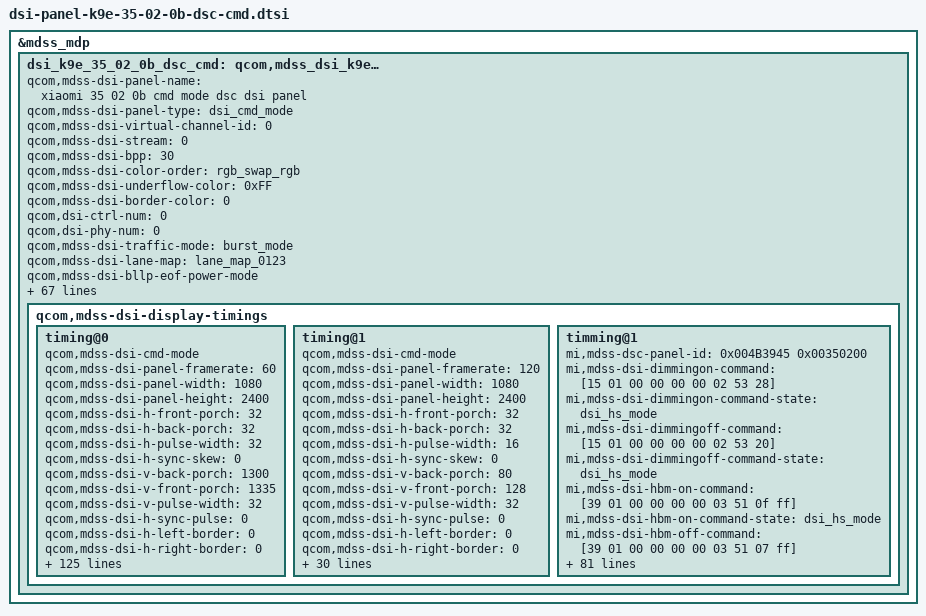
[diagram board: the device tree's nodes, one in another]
&mdss_mdp {
	dsi_k9e_35_02_0b_dsc_cmd: qcom,mdss_dsi_k9e_35_02_0b_dsc_cmd {
		qcom,mdss-dsi-panel-name = "xiaomi 35 02 0b cmd mode dsc dsi panel";
		qcom,mdss-dsi-panel-type = "dsi_cmd_mode";
		qcom,mdss-dsi-virtual-channel-id = <0>;
		qcom,mdss-dsi-stream = <0>;
		qcom,mdss-dsi-bpp = <30>;
		qcom,mdss-dsi-color-order = "rgb_swap_rgb";
		qcom,mdss-dsi-underflow-color = <0xFF>;
		qcom,mdss-dsi-border-color = <0>;
		qcom,dsi-ctrl-num = <0>;
		qcom,dsi-phy-num = <0>;
		qcom,mdss-dsi-traffic-mode = "burst_mode";
		qcom,mdss-dsi-lane-map = "lane_map_0123";
		qcom,mdss-dsi-bllp-eof-power-mode;
		qcom,mdss-dsi-bllp-power-mode;
		qcom,mdss-dsi-lane-0-state;
		qcom,mdss-dsi-lane-1-state;
		qcom,mdss-dsi-lane-2-state;
		qcom,mdss-dsi-lane-3-state;
		qcom,mdss-dsi-dma-trigger = "trigger_sw";
		qcom,mdss-dsi-mdp-trigger = "none";
		qcom,mdss-dsi-reset-sequence = <1 11>, <0 1>, <1 11>;
		qcom,mdss-pan-physical-width-dimension = <68>;
		qcom,mdss-pan-physical-height-dimension = <152>;
		qcom,mdss-dsi-te-pin-select = <1>;
		qcom,mdss-dsi-wr-mem-start = <0x2c>;
		qcom,mdss-dsi-wr-mem-continue = <0x3c>;
		qcom,mdss-dsi-te-dcs-command = <1>;
		qcom,mdss-dsi-te-check-enable;
		qcom,mdss-dsi-te-using-te-pin;
		qcom,mdss-dsi-tx-eot-append;
		qcom,mdss-dsi-lp11-init;
		qcom,bl-update-flag = "delay_until_first_frame";
		qcom,mdss-dsi-panel-mode-switch;
		qcom,mdss-dsi-panel-hdr-enabled;
		qcom,mdss-dsi-panel-hdr-color-primaries = <14500 15500 32000 17000 15500 30000 8000 3000>;
		qcom,mdss-dsi-panel-peak-brightness = <4200000>;
		qcom,mdss-dsi-panel-blackness-level = <3230>;

		qcom,mdss-dsi-display-timings {

			timing@0 {
				qcom,mdss-dsi-cmd-mode;
				qcom,mdss-dsi-panel-framerate = <60>;
				qcom,mdss-dsi-panel-width = <1080>;
				qcom,mdss-dsi-panel-height = <2400>;
				qcom,mdss-dsi-h-front-porch = <32>;
				qcom,mdss-dsi-h-back-porch = <32>;
				qcom,mdss-dsi-h-pulse-width = <32>;
				qcom,mdss-dsi-h-sync-skew = <0>;
				qcom,mdss-dsi-v-back-porch = <1300>;
				qcom,mdss-dsi-v-front-porch = <1335>;
				qcom,mdss-dsi-v-pulse-width = <32>;
				qcom,mdss-dsi-h-sync-pulse = <0>;
				qcom,mdss-dsi-h-left-border = <0>;
				qcom,mdss-dsi-h-right-border = <0>;
				qcom,mdss-dsi-v-top-border = <0>;
				qcom,mdss-dsi-v-bottom-border = <0>;
				qcom,mdss-dsi-panel-clockrate = <831000000>;
				qcom,mdss-dsi-panel-jitter = <0x05 0x01>;
				qcom,mdss-mdp-transfer-time-us = <8000>;
				qcom,mdss-dsi-on-command = [39 01 00 00 00 00 02 90 01 39 01 00 00 00 00 13 91 ab 28 00 0c c2 00 03 1c 01 7e 00 0f 08 bb 04 3d 10 f0 39 01 00 00 00 00 02 03 01 39 01 00 00 00 00 02 2c 00 39 01 00 00 00 00 02 35 00 39 01 00 00 00 00 05 2a 00 00 04 37 39 01 00 00 00 00 05 2b 00 00 09 5f 39 01 00 00 00 00 02 53 20 39 01 00 00 00 00 06 f0 55 aa 52 08 00 39 00 00 00 00 00 02 6f 01 39 00 00 00 00 00 02 c0 b3 39 00 00 00 00 00 02 6f 11 39 01 00 00 00 00 02 c0 30 39 00 00 00 00 00 02 b2 19 39 00 00 00 00 00 02 6f 02 39 01 00 00 00 00 03 b2 08 08 39 01 00 00 00 00 05 51 00 00 0f fe 39 01 00 00 00 00 02 2f 01 39 00 00 00 00 00 02 b5 94 39 00 00 00 00 00 02 82 ae 39 01 00 00 00 00 02 5f 01 39 00 00 00 00 00 03 be 0e 0b 39 00 00 00 00 00 02 6f 05 39 00 00 00 00 00 02 be 88 39 00 00 00 00 00 02 6f 1f 39 00 00 00 00 00 03 b2 00 30 39 00 00 00 00 00 02 6f 17 39 01 00 00 00 00 03 b2 07 ff 39 01 00 00 00 00 06 f0 55 aa 52 08 07 39 00 00 00 00 00 03 c0 05 02 39 00 00 00 00 00 02 6f 04 39 00 00 00 00 00 03 c0 55 00 39 01 00 00 00 00 2c c1 30 0f 03 c1 0b d1 f2 ae 3f fc dc aa 3f f9 27 4a 80 00 a7 e2 79 00 1a 00 00 85 1f 33 b0 0c f5 0f e1 95 00 00 00 14 18 00 19 1f 00 39 01 00 00 00 00 2c c2 38 0f 0d 99 02 71 f4 7a 3f f9 f8 d6 ff fd e2 02 00 00 75 80 91 00 00 20 00 19 8f 33 f0 0a d7 0f 91 e7 00 00 04 1e 18 04 23 1f 00 39 01 00 00 00 00 2c c3 36 00 03 c1 0b d1 0d 52 00 00 00 00 3f f3 96 04 80 00 00 00 00 03 b2 00 04 1d 1f 33 b0 00 00 03 1f 95 00 00 90 14 40 90 19 47 00 39 01 00 00 00 00 2c c4 3e 00 0d 99 02 71 0b 86 00 03 5f 48 ff fc c1 ec 00 00 00 00 00 04 1e 20 04 37 8f 33 f0 00 00 03 6f e7 00 00 94 1e 40 94 23 47 00 39 01 00 00 00 00 2c c5 2c 00 0d 99 02 71 0b 86 3f f4 f9 bc c0 00 00 00 00 00 00 00 00 80 00 d0 90 19 3f 33 f0 00 00 0c 91 19 00 00 00 00 00 00 00 00 00 39 01 00 00 00 00 2c c6 2c 00 03 c1 0b d1 0d 52 3f fb 3f bc 00 03 fc 18 00 00 00 00 00 90 1a 40 90 85 5f 33 30 00 00 0c e1 6b 00 00 00 00 00 00 00 00 00 39 01 00 00 00 00 2c c7 2a 0f 03 c1 0b d1 f2 ae 00 01 9c ee 00 09 8d 5e 7f fe ab 86 0d 93 b2 40 94 1d 5f 33 3f f3 0b 00 1f 6b 00 00 00 00 00 00 00 00 00 39 01 00 00 00 00 2c c8 2a 0f 0d 99 02 71 f4 7a 00 08 5e 62 c0 01 20 16 7f ff 0d 95 e5 84 1e d0 94 37 3f 33 ff f5 29 00 6f 19 00 00 00 00 00 00 00 00 00 39 01 00 00 00 00 2c c9 21 00 28 a4 28 a4 00 00 3f df 9d 50 3f df 9d 50 80 06 73 a9 10 00 00 00 00 66 66 33 d0 28 a4 0f 9a 9a 00 00 00 00 00 00 00 00 00 39 01 00 00 00 00 2c ca 27 00 28 a4 27 d9 00 00 00 00 00 00 3f e0 3f 14 80 00 00 00 00 00 67 00 00 cc 66 33 d0 00 00 03 66 9b 00 00 00 00 00 00 00 00 00 39 01 00 00 00 00 2c cb 2d 00 27 d9 28 a4 00 00 3f e0 3f 14 80 00 00 00 00 00 00 00 00 00 00 67 00 66 cc 33 70 00 00 0c 9b 66 00 00 00 00 00 00 00 00 00 39 01 00 00 00 00 2c cc 2b 00 27 d9 27 d9 00 00 00 00 00 00 80 00 00 00 7f f9 cc 2a 0f 00 67 67 00 cc cc 33 7f d8 27 00 65 65 00 00 00 00 00 00 00 00 00 39 01 00 00 00 00 2c cd 2d 00 03 c1 03 c1 00 00 3f ff 17 42 00 00 00 00 80 00 00 00 00 01 fc 3f 02 1b 5e 33 50 00 00 0c e1 1f 00 00 00 00 00 00 00 00 00 39 01 00 00 00 00 2c ce 2b 00 03 c1 03 c1 00 00 00 00 00 00 00 00 00 00 ff ff f1 e8 7f 02 1c 3f 02 3b 5e 33 5f fc 3f 00 1f 1f 00 00 00 00 00 00 00 00 00 39 01 00 00 00 00 2c cf 21 00 03 c1 03 84 00 00 3f ff 1e c4 3f ff 26 08 00 00 0d 32 84 01 fc 1f 02 1a 3e 33 80 03 a2 0f e1 e2 00 00 00 00 00 00 00 00 00 39 01 00 00 00 00 2c d0 27 00 03 c1 04 00 00 00 00 00 00 00 3f ff 08 00 00 00 00 00 00 02 1b 1f 02 3b 3e 33 90 00 00 03 1f e0 00 00 00 00 00 00 00 00 00 39 01 00 00 00 00 06 f0 55 aa 52 08 01 39 00 00 00 00 00 02 6f 01 39 00 00 00 00 00 04 d2 00 00 11 39 00 00 00 00 00 02 6f 06 39 00 00 00 00 00 02 d2 05 39 00 00 00 00 00 02 6f 09 39 00 00 00 00 00 03 d2 00 00 39 00 00 00 00 00 02 6f 0f 39 00 00 00 00 00 02 d2 00 39 00 00 00 00 00 02 ce 00 39 01 00 00 00 00 05 ff aa 55 a5 80 39 00 00 00 00 00 02 6f 61 39 00 00 00 00 00 02 f3 80 39 01 00 00 00 00 06 f0 55 aa 52 08 00 39 00 00 00 00 00 02 c0 46 39 00 00 00 00 00 02 6f 06 39 01 00 00 00 00 04 b5 2d 19 32 39 00 00 00 00 00 02 6f 0b 39 01 00 00 00 00 04 b5 33 23 2d 39 00 00 00 00 00 02 6f 02 39 01 00 00 00 00 03 ec 80 10 39 00 00 00 00 00 06 f0 55 aa 52 08 01 39 01 00 00 00 00 02 ce 08 39 01 00 00 78 00 02 11 00 39 01 00 00 00 00 02 29 00 39 00 00 00 00 00 06 f0 55 aa 52 08 01 39 01 00 00 00 00 02 ce 00];
				qcom,mdss-dsi-off-command = [39 01 00 00 0a 00 02 28 00 39 01 00 00 64 00 02 10 00];
				qcom,mdss-dsi-on-command-state = "dsi_lp_mode";
				qcom,mdss-dsi-off-command-state = "dsi_lp_mode";
				qcom,mdss-dsi-timing-switch-command = [39 01 00 00 14 00 02 2f 01];
				qcom,mdss-dsi-timing-switch-command-state = "dsi_hs_mode";
				qcom,mdss-dsi-lp1-command = [39 01 00 00 14 00 02 39 00];
				qcom,mdss-dsi-lp1-command-state = "dsi_hs_mode";
				qcom,mdss-dsi-nolp-command = [39 01 00 00 14 00 02 38 00];
				qcom,mdss-dsi-nolp-command-state = "dsi_hs_mode";
				qcom,compression-mode = "dsc";
				qcom,mdss-dsc-version = <0x11>;
				qcom,mdss-dsc-scr-version = <0x0>;
				qcom,mdss-dsc-slice-height = <12>;
				qcom,mdss-dsc-slice-width = <1080>;
				qcom,mdss-dsc-slice-per-pkt = <1>;
				qcom,mdss-dsc-bit-per-component = <10>;
				qcom,mdss-dsc-bit-per-pixel = <8>;
				qcom,mdss-dsc-block-prediction-enable;
			};

			timing@1 {
				qcom,mdss-dsi-cmd-mode;
				qcom,mdss-dsi-panel-framerate = <120>;
				qcom,mdss-dsi-panel-width = <1080>;
				qcom,mdss-dsi-panel-height = <2400>;
				qcom,mdss-dsi-h-front-porch = <32>;
				qcom,mdss-dsi-h-back-porch = <32>;
				qcom,mdss-dsi-h-pulse-width = <16>;
				qcom,mdss-dsi-h-sync-skew = <0>;
				qcom,mdss-dsi-v-back-porch = <80>;
				qcom,mdss-dsi-v-front-porch = <128>;
				qcom,mdss-dsi-v-pulse-width = <32>;
				qcom,mdss-dsi-h-sync-pulse = <0>;
				qcom,mdss-dsi-h-left-border = <0>;
				qcom,mdss-dsi-h-right-border = <0>;
				qcom,mdss-dsi-v-top-border = <0>;
				qcom,mdss-dsi-v-bottom-border = <0>;
				qcom,mdss-dsi-panel-clockrate = <831000000>;
				qcom,mdss-dsi-panel-jitter = <0x05 0x01>;
				qcom,mdss-mdp-transfer-time-us = <8000>;
				qcom,mdss-dsi-on-command = [39 01 00 00 00 00 02 90 01 39 01 00 00 00 00 13 91 89 28 00 0c c2 00 03 1c 01 7e 00 0f 08 bb 04 3d 10 f0 39 01 00 00 00 00 02 03 01 39 01 00 00 00 00 02 2c 00 39 01 00 00 00 00 02 35 00 39 01 00 00 00 00 05 2a 00 00 04 37 39 01 00 00 00 00 05 2b 00 00 09 5f 39 01 00 00 00 00 02 53 20 39 01 00 00 00 00 06 f0 55 aa 52 08 00 39 00 00 00 00 00 02 6f 01 39 00 00 00 00 00 02 c0 b3 39 00 00 00 00 00 02 6f 11 39 01 00 00 00 00 02 c0 30 39 00 00 00 00 00 02 b2 19 39 00 00 00 00 00 02 6f 02 39 01 00 00 00 00 03 b2 08 08 39 01 00 00 00 00 05 51 00 00 0f fe 39 01 00 00 00 00 02 2f 02 39 00 00 00 00 00 02 b5 94 39 00 00 00 00 00 02 82 ae 39 01 00 00 00 00 02 5f 01 39 00 00 00 00 00 03 be 0e 0b 39 00 00 00 00 00 02 6f 05 39 00 00 00 00 00 02 be 88 39 00 00 00 00 00 02 6f 1f 39 00 00 00 00 00 03 b2 00 30 39 00 00 00 00 00 02 6f 17 39 01 00 00 00 00 03 b2 07 ff 39 01 00 00 00 00 06 f0 55 aa 52 08 07 39 00 00 00 00 00 03 c0 05 02 39 00 00 00 00 00 02 6f 04 39 00 00 00 00 00 03 c0 55 00 39 01 00 00 00 00 2c c1 30 0f 03 c1 0b d1 f2 ae 3f fc dc aa 3f f9 27 4a 80 00 a7 e2 79 00 1a 00 00 85 1f 33 b0 0c f5 0f e1 95 00 00 00 14 18 00 19 1f 00 39 01 00 00 00 00 2c c2 38 0f 0d 99 02 71 f4 7a 3f f9 f8 d6 ff fd e2 02 00 00 75 80 91 00 00 20 00 19 8f 33 f0 0a d7 0f 91 e7 00 00 04 1e 18 04 23 1f 00 39 01 00 00 00 00 2c c3 36 00 03 c1 0b d1 0d 52 00 00 00 00 3f f3 96 04 80 00 00 00 00 03 b2 00 04 1d 1f 33 b0 00 00 03 1f 95 00 00 90 14 40 90 19 47 00 39 01 00 00 00 00 2c c4 3e 00 0d 99 02 71 0b 86 00 03 5f 48 ff fc c1 ec 00 00 00 00 00 04 1e 20 04 37 8f 33 f0 00 00 03 6f e7 00 00 94 1e 40 94 23 47 00 39 01 00 00 00 00 2c c5 2c 00 0d 99 02 71 0b 86 3f f4 f9 bc c0 00 00 00 00 00 00 00 00 80 00 d0 90 19 3f 33 f0 00 00 0c 91 19 00 00 00 00 00 00 00 00 00 39 01 00 00 00 00 2c c6 2c 00 03 c1 0b d1 0d 52 3f fb 3f bc 00 03 fc 18 00 00 00 00 00 90 1a 40 90 85 5f 33 30 00 00 0c e1 6b 00 00 00 00 00 00 00 00 00 39 01 00 00 00 00 2c c7 2a 0f 03 c1 0b d1 f2 ae 00 01 9c ee 00 09 8d 5e 7f fe ab 86 0d 93 b2 40 94 1d 5f 33 3f f3 0b 00 1f 6b 00 00 00 00 00 00 00 00 00 39 01 00 00 00 00 2c c8 2a 0f 0d 99 02 71 f4 7a 00 08 5e 62 c0 01 20 16 7f ff 0d 95 e5 84 1e d0 94 37 3f 33 ff f5 29 00 6f 19 00 00 00 00 00 00 00 00 00 39 01 00 00 00 00 2c c9 21 00 28 a4 28 a4 00 00 3f df 9d 50 3f df 9d 50 80 06 73 a9 10 00 00 00 00 66 66 33 d0 28 a4 0f 9a 9a 00 00 00 00 00 00 00 00 00 39 01 00 00 00 00 2c ca 27 00 28 a4 27 d9 00 00 00 00 00 00 3f e0 3f 14 80 00 00 00 00 00 67 00 00 cc 66 33 d0 00 00 03 66 9b 00 00 00 00 00 00 00 00 00 39 01 00 00 00 00 2c cb 2d 00 27 d9 28 a4 00 00 3f e0 3f 14 80 00 00 00 00 00 00 00 00 00 00 67 00 66 cc 33 70 00 00 0c 9b 66 00 00 00 00 00 00 00 00 00 39 01 00 00 00 00 2c cc 2b 00 27 d9 27 d9 00 00 00 00 00 00 80 00 00 00 7f f9 cc 2a 0f 00 67 67 00 cc cc 33 7f d8 27 00 65 65 00 00 00 00 00 00 00 00 00 39 01 00 00 00 00 2c cd 2d 00 03 c1 03 c1 00 00 3f ff 17 42 00 00 00 00 80 00 00 00 00 01 fc 3f 02 1b 5e 33 50 00 00 0c e1 1f 00 00 00 00 00 00 00 00 00 39 01 00 00 00 00 2c ce 2b 00 03 c1 03 c1 00 00 00 00 00 00 00 00 00 00 ff ff f1 e8 7f 02 1c 3f 02 3b 5e 33 5f fc 3f 00 1f 1f 00 00 00 00 00 00 00 00 00 39 01 00 00 00 00 2c cf 21 00 03 c1 03 84 00 00 3f ff 1e c4 3f ff 26 08 00 00 0d 32 84 01 fc 1f 02 1a 3e 33 80 03 a2 0f e1 e2 00 00 00 00 00 00 00 00 00 39 01 00 00 00 00 2c d0 27 00 03 c1 04 00 00 00 00 00 00 00 3f ff 08 00 00 00 00 00 00 02 1b 1f 02 3b 3e 33 90 00 00 03 1f e0 00 00 00 00 00 00 00 00 00 39 01 00 00 00 00 06 f0 55 aa 52 08 01 39 00 00 00 00 00 02 6f 01 39 00 00 00 00 00 04 d2 00 00 11 39 00 00 00 00 00 02 6f 06 39 00 00 00 00 00 02 d2 05 39 00 00 00 00 00 02 6f 09 39 00 00 00 00 00 03 d2 00 00 39 00 00 00 00 00 02 6f 0f 39 00 00 00 00 00 02 d2 00 39 00 00 00 00 00 02 ce 00 39 01 00 00 00 00 05 ff aa 55 a5 80 39 00 00 00 00 00 02 6f 61 39 00 00 00 00 00 02 f3 80 39 01 00 00 00 00 06 f0 55 aa 52 08 00 39 00 00 00 00 00 02 c0 46 39 00 00 00 00 00 02 6f 06 39 01 00 00 00 00 04 b5 2d 19 32 39 00 00 00 00 00 02 6f 0b 39 01 00 00 00 00 04 b5 33 23 2d 39 00 00 00 00 00 02 6f 02 39 01 00 00 00 00 03 ec 80 10 39 00 00 00 00 00 06 f0 55 aa 52 08 01 39 01 00 00 00 00 02 ce 08 39 01 00 00 78 00 02 11 00 39 01 00 00 00 00 02 29 00 39 00 00 00 00 00 06 f0 55 aa 52 08 01 39 01 00 00 00 00 02 ce 00];
				qcom,mdss-dsi-off-command = [39 01 00 00 0a 00 02 28 00 39 01 00 00 64 00 02 10 00];
				qcom,mdss-dsi-on-command-state = "dsi_lp_mode";
				qcom,mdss-dsi-off-command-state = "dsi_lp_mode";
				qcom,mdss-dsi-timing-switch-command = [39 01 00 00 14 00 02 2f 02];
				qcom,mdss-dsi-timing-switch-command-state = "dsi_hs_mode";
				qcom,mdss-dsi-lp1-command = [39 01 00 00 14 00 02 39 00];
				qcom,mdss-dsi-lp1-command-state = "dsi_hs_mode";
				qcom,mdss-dsi-nolp-command = [39 01 00 00 14 00 02 38 00];
				qcom,mdss-dsi-nolp-command-state = "dsi_hs_mode";
				qcom,compression-mode = "dsc";
				qcom,mdss-dsc-version = <0x11>;
				qcom,mdss-dsc-scr-version = <0x0>;
				qcom,mdss-dsc-slice-height = <12>;
				qcom,mdss-dsc-slice-width = <1080>;
				qcom,mdss-dsc-slice-per-pkt = <1>;
				qcom,mdss-dsc-bit-per-component = <10>;
				qcom,mdss-dsc-bit-per-pixel = <8>;
				qcom,mdss-dsc-block-prediction-enable;
			};
		};
	};
};

&dsi_k9e_35_02_0b_dsc_cmd {
	mi,panel-id = <0x004B3945 0x00350200>;
	mi,hbm-51-ctl-flag;
	mi,bl-51ctl-32bit-flag;
	mi,aod-bl-51ctl-flag;
	mi,aod-brightness = <0x154 0xFFE>;
	mi,hbm-off-51-index = <0>;
	mi,hbm-fod-off-51-index = <1>;
	mi,hbm-bl-min-level = <1>;
	mi,hbm-bl-max-level = <2047>;
	mi,max-brightness-clone = <4095>;
	mi,thermal-dimming-flag;
	mi,mdss-dsi-panel-dc-type = <0>;
	mi,local-hbm-enabled;
	mi,local-hbm-off-to-hbm-51-index = <1>;
	mi,local-hbm-off-to-normal-51-index = <1>;
	mi,local-hbm-on-87-index = <11>;
	mi,local-hbm-hlpm-on-87-index = <13>;
	mi,local-hbm-on-d0-index = <2>;
	mi,local-hbm-hlpm-on-d0-index = <4>;
	mi,doze-hbm-dbv-level = <245>;
	mi,doze-lbm-dbv-level = <20>;
	mi,fod-low-brightness-clone-threshold = <38>;
	mi,fod-low-brightness-lux-threshold = <1>;
	mi,panel-hbm-backlight-threshold = <2047>;
	mi,lhbm-update-flag;
	mi,esd-err-irq-gpio = <&tlmm 3 0x2002>;
	mi,panel-aod-to-off-command-need-enabled;
	mi,panel-on-dimming-delay = <120>;

	qcom,esd-check-enabled;
	qcom,esd-aod-check-enabled;
	qcom,mdss-dsi-panel-status-check-mode = "reg_read";
	qcom,mdss-dsi-panel-status-offset-command = [39 01 00 00 00 00 05 ff aa 55 a5 81 39 01 00 00 00 00 02 6f 0f];
	qcom,mdss-dsi-panel-status-command = <0x6010000 0x1fa>;
	qcom,mdss-dsi-panel-status-command-state = "dsi_lp_mode";
	qcom,mdss-dsi-panel-status-offset-command-state = "dsi_lp_mode";
	qcom,mdss-dsi-panel-status-value = <0x0>;
	qcom,mdss-dsi-panel-status-read-length = <1>;

	qcom,mdss-dsi-display-timings {

		timing@0 {
			mi,mdss-dsc-panel-id = <0x004B3945 0x00350200>;
			mi,mdss-dsi-dimmingon-command = [15 01 00 00 00 00 02 53 28];
			mi,mdss-dsi-dimmingon-command-state = "dsi_hs_mode";
			mi,mdss-dsi-dimmingoff-command = [15 01 00 00 00 00 02 53 20];
			mi,mdss-dsi-dimmingoff-command-state = "dsi_hs_mode";
			mi,mdss-dsi-hbm-on-command = [39 01 00 00 00 00 03 51 0f ff];
			mi,mdss-dsi-hbm-on-command-state = "dsi_hs_mode";
			mi,mdss-dsi-hbm-off-command = [39 01 00 00 00 00 03 51 07 ff];
			mi,mdss-dsi-hbm-off-command-state = "dsi_hs_mode";
			mi,mdss-dsi-doze-hbm-command = [39 01 00 00 00 00 05 51 00 f5 0f fe 39 01 00 00 14 00 02 39 00];
			mi,mdss-dsi-doze-hbm-command-state = "dsi_hs_mode";
			mi,mdss-dsi-doze-lbm-command = [39 01 00 00 00 00 05 51 00 14 01 54 39 01 00 00 14 00 02 39 00];
			mi,mdss-dsi-doze-lbm-command-state = "dsi_hs_mode";
			mi,mdss-dsi-doze-hbm-nolp-command = [39 01 00 00 00 00 05 51 00 f5 0f fe 39 01 00 00 14 00 02 38 00];
			mi,mdss-dsi-doze-hbm-nolp-command-state = "dsi_hs_mode";
			mi,mdss-dsi-doze-lbm-nolp-command = [39 01 00 00 00 00 05 51 00 14 07 ff 39 01 00 00 14 00 02 38 00];
			mi,mdss-dsi-doze-lbm-nolp-command-state = "dsi_hs_mode";
			mi,mdss-dsi-hbm-fod-on-command = [39 01 00 00 00 00 02 53 20 39 00 00 00 00 00 03 51 0f fe 39 01 00 00 00 00 04 87 00 00 04];
			mi,mdss-dsi-hbm-fod-on-command-state = "dsi_hs_mode";
			mi,mdss-dsi-hbm-fod-off-command = [39 01 00 00 00 00 02 53 20 39 00 00 00 00 00 03 51 07 ff 39 01 00 00 00 00 04 87 00 00 04];
			mi,mdss-dsi-hbm-fod-off-command-state = "dsi_hs_mode";
			mi,mdss-dsi-doze-none-nolp-command = [39 01 00 00 00 00 02 38 00];
			mi,mdss-dsi-doze-none-nolp-command-state = "dsi_hs_mode";
			mi,mdss-dsi-local-hbm-normal-white-1000nit-command = <0x39010000 0x6f0 0x55aa5208 0x2390000 0x02 0x6f083900 0x0 0x7d00adc 0x9b00c9e 0x39000000 0x10d1 0x1000000 0x67006700 0x0 0xcc00cc39 0x0 0x26f0f 0x39000000 0x7d1 0x3ffc3ffc 0x3ffc3900 0x0 0x6f055aa 0x52080739 0x0 0x2d940 0x39000000 0x288 0x1390000 0x02 0x6f013900 0x0 0x588021d 0x8633900 0x0 0x3871fff 0x39000000 0x351 0x7ff3900 0x0 0x2880139 0x1000042 0x28501>;
			mi,mdss-dsi-local-hbm-normal-white-1000nit-command-state = "dsi_hs_mode";
			mi,mdss-dsi-local-hbm-hlpm-white-1000nit-command = [39 01 00 00 00 00 06 f0 55 aa 52 08 00 39 00 00 00 00 00 02 38 00 39 00 00 00 00 00 06 f0 55 aa 52 08 02 39 00 00 00 00 00 02 6f 08 39 00 00 00 00 00 07 d0 0a dc 09 b0 0c 9e 39 00 00 00 00 00 10 d1 01 00 00 00 67 00 67 00 00 00 00 00 cc 00 cc 39 00 00 00 00 00 02 6f 0f 39 00 00 00 00 00 07 d1 3f fc 3f fc 3f fc 39 00 00 00 00 00 06 f0 55 aa 52 08 07 39 00 00 00 00 00 02 d9 40 39 00 00 00 00 00 02 88 01 39 00 00 00 00 00 02 6f 01 39 00 00 00 00 00 05 88 02 1d 08 63 39 00 00 00 00 00 03 87 1f ff 39 00 00 00 00 00 03 51 07 ff 39 00 00 00 00 00 02 88 01 39 01 00 00 42 00 02 85 01];
			mi,mdss-dsi-local-hbm-hlpm-white-1000nit-command-state = "dsi_hs_mode";
			mi,mdss-dsi-local-hbm-normal-white-110nit-command = <0x39010000 0x6f0 0x55aa5208 0x2390000 0x02 0x6f083900 0x0 0x7d00746 0x6900881 0x39000000 0x10d1 0x1000000 0x67006700 0x0 0xcc00cc39 0x0 0x26f0f 0x39000000 0x7d1 0x3ffc3ffc 0x3ffc3900 0x0 0x6f055aa 0x52080739 0x0 0x2d940 0x39000000 0x288 0x1390000 0x02 0x6f013900 0x0 0x588021d 0x8633900 0x0 0x3871fff 0x39000000 0x351 0x7ff3900 0x0 0x2880139 0x1000042 0x28501>;
			mi,mdss-dsi-local-hbm-normal-white-110nit-command-state = "dsi_hs_mode";
			mi,mdss-dsi-local-hbm-hlpm-white-110nit-command = [39 01 00 00 00 00 06 f0 55 aa 52 08 02 39 00 00 00 00 00 02 38 00 39 00 00 00 00 00 06 f0 55 aa 52 08 02 39 00 00 00 00 00 02 6f 08 39 00 00 00 00 00 07 d0 07 46 06 90 08 81 39 00 00 00 00 00 10 d1 01 00 00 00 67 00 67 00 00 00 00 00 cc 00 cc 39 00 00 00 00 00 02 6f 0f 39 00 00 00 00 00 07 d1 3f fc 3f fc 3f fc 39 00 00 00 00 00 06 f0 55 aa 52 08 07 39 00 00 00 00 00 02 d9 40 39 00 00 00 00 00 02 88 01 39 00 00 00 00 00 02 6f 01 39 00 00 00 00 00 05 88 02 1d 08 63 39 00 00 00 00 00 03 87 1f ff 39 00 00 00 00 00 03 51 07 ff 39 00 00 00 00 00 02 88 01 39 01 00 00 42 00 02 85 01];
			mi,mdss-dsi-local-hbm-hlpm-white-110nit-command-state = "dsi_hs_mode";
			mi,mdss-dsi-local-hbm-normal-green-500nit-command = <0x39010000 0x6f0 0x55aa5208 0x2390000 0x02 0x6f083900 0x0 0x7d00000 0x9190000 0x39000000 0x10d1 0x1000000 0x67006700 0x0 0xcc00cc39 0x0 0x26f0f 0x39000000 0x7d1 0x3ffc3ffc 0x3ffc3900 0x0 0x6f055aa 0x52080739 0x0 0x2d940 0x39000000 0x288 0x1390000 0x02 0x6f013900 0x0 0x588021d 0x8633900 0x0 0x3871fff 0x39000000 0x351 0x7ff3900 0x0 0x2880139 0x1000042 0x28501>;
			mi,mdss-dsi-local-hbm-normal-green-500nit-command-state = "dsi_hs_mode";
			mi,mdss-dsi-local-hbm-off-to-normal-command = [39 01 00 00 00 00 02 53 20 39 00 00 00 00 00 03 51 00 00 39 00 00 00 00 00 03 87 0f ff 39 00 00 00 00 00 02 88 01 39 01 00 00 00 00 02 86 01];
			mi,mdss-dsi-local-hbm-off-to-normal-command-state = "dsi_hs_mode";
			mi,mdss-dsi-local-hbm-off-to-hbm-command = [39 01 00 00 00 00 02 53 20 39 00 00 00 00 00 03 51 00 00 39 00 00 00 00 00 03 87 0f ff 39 00 00 00 00 00 02 88 01 39 01 00 00 00 00 02 86 01];
			mi,mdss-dsi-local-hbm-off-to-hbm-command-state = "dsi_hs_mode";
			mi,mdss-dsi-local-hbm-off-to-hlpm-command = <0x39010000 0x253 0x20390000 0x03 0x51000039 0x0 0x3870f 0xff390000 0x02 0x88013901 0x0 0x2860139 0x0 0x55100 0xf50ffe39 0x1000000 0x23900>;
			mi,mdss-dsi-local-hbm-off-to-hlpm-command-state = "dsi_hs_mode";
			mi,mdss-dsi-local-hbm-off-to-llpm-command = <0x39010000 0x253 0x20390000 0x03 0x51000039 0x0 0x3870f 0xff390000 0x02 0x88013901 0x0 0x2860139 0x0 0x55100 0x1407ff39 0x1000000 0x23900>;
			mi,mdss-dsi-local-hbm-off-to-llpm-command-state = "dsi_hs_mode";
			mi,mdss-dsi-flat-mode-on-command = [39 01 00 00 00 00 06 f0 55 aa 52 08 00 39 00 00 00 00 00 02 5f 00 39 01 00 00 14 00 02 2f 03];
			mi,mdss-dsi-flat-mode-on-command-state = "dsi_hs_mode";
			mi,mdss-dsi-flat-mode-off-command = [39 01 00 00 00 00 06 f0 55 aa 52 08 00 39 00 00 00 00 00 02 5f 01 39 01 00 00 14 00 02 2f 01];
			mi,mdss-dsi-flat-mode-off-command-state = "dsi_hs_mode";
			mi,mdss-dsi-timing-switch-gir-command = [39 01 00 00 14 00 02 2f 03];
			mi,mdss-dsi-timing-switch-gir-command-state = "dsi_hs_mode";
			mi,mdss-dsi-pre-doze-to-off-command = [39 01 00 00 00 00 06 f0 55 aa 52 08 01 39 01 00 00 00 00 02 ce 0c];
			mi,mdss-dsi-pre-doze-to-off-command-state = "dsi_hs_mode";
		};

		timming@1 {
			mi,mdss-dsc-panel-id = <0x004B3945 0x00350200>;
			mi,mdss-dsi-dimmingon-command = [15 01 00 00 00 00 02 53 28];
			mi,mdss-dsi-dimmingon-command-state = "dsi_hs_mode";
			mi,mdss-dsi-dimmingoff-command = [15 01 00 00 00 00 02 53 20];
			mi,mdss-dsi-dimmingoff-command-state = "dsi_hs_mode";
			mi,mdss-dsi-hbm-on-command = [39 01 00 00 00 00 03 51 0f ff];
			mi,mdss-dsi-hbm-on-command-state = "dsi_hs_mode";
			mi,mdss-dsi-hbm-off-command = [39 01 00 00 00 00 03 51 07 ff];
			mi,mdss-dsi-hbm-off-command-state = "dsi_hs_mode";
			mi,mdss-dsi-doze-hbm-command = [39 01 00 00 00 00 05 51 00 f5 0f fe 39 01 00 00 14 00 02 39 00];
			mi,mdss-dsi-doze-hbm-command-state = "dsi_hs_mode";
			mi,mdss-dsi-doze-lbm-command = [39 01 00 00 00 00 05 51 00 14 01 54 39 01 00 00 14 00 02 39 00];
			mi,mdss-dsi-doze-lbm-command-state = "dsi_hs_mode";
			mi,mdss-dsi-doze-hbm-nolp-command = [39 01 00 00 00 00 05 51 00 f5 0f fe 39 01 00 00 14 00 02 38 00];
			mi,mdss-dsi-doze-hbm-nolp-command-state = "dsi_hs_mode";
			mi,mdss-dsi-doze-lbm-nolp-command = [39 01 00 00 00 00 05 51 00 14 07 ff 39 01 00 00 14 00 02 38 00];
			mi,mdss-dsi-doze-lbm-nolp-command-state = "dsi_hs_mode";
			mi,mdss-dsi-hbm-fod-on-command = [39 01 00 00 00 00 02 53 20 39 00 00 00 00 00 03 51 0f fe 39 01 00 00 00 00 04 87 00 00 04];
			mi,mdss-dsi-hbm-fod-on-command-state = "dsi_hs_mode";
			mi,mdss-dsi-hbm-fod-off-command = [39 01 00 00 00 00 02 53 20 39 00 00 00 00 00 03 51 07 ff 39 01 00 00 00 00 02 87 00 00 04];
			mi,mdss-dsi-hbm-fod-off-command-state = "dsi_hs_mode";
			mi,mdss-dsi-doze-none-nolp-command = [39 01 00 00 14 00 02 38 00];
			mi,mdss-dsi-doze-none-nolp-command-state = "dsi_hs_mode";
			mi,mdss-dsi-local-hbm-normal-white-1000nit-command = <0x39010000 0x6f0 0x55aa5208 0x2390000 0x02 0x6f083900 0x0 0x7d00adc 0x9b00c9e 0x39000000 0x10d1 0x1000000 0x67006700 0x0 0xcc00cc39 0x0 0x26f0f 0x39000000 0x7d1 0x3ffc3ffc 0x3ffc3900 0x0 0x6f055aa 0x52080739 0x0 0x2d940 0x39000000 0x288 0x1390000 0x02 0x6f013900 0x0 0x588021d 0x8633900 0x0 0x3871fff 0x39000000 0x351 0x7ff3900 0x0 0x2880139 0x1000042 0x28501>;
			mi,mdss-dsi-local-hbm-normal-white-1000nit-command-state = "dsi_hs_mode";
			mi,mdss-dsi-local-hbm-hlpm-white-1000nit-command = [39 01 00 00 00 00 06 f0 55 aa 52 08 00 39 00 00 00 00 00 02 38 00 39 00 00 00 00 00 06 f0 55 aa 52 08 02 39 00 00 00 00 00 02 6f 08 39 00 00 00 00 00 07 d0 0a dc 09 b0 0c 9e 39 00 00 00 00 00 10 d1 01 00 00 00 67 00 67 00 00 00 00 00 cc 00 cc 39 00 00 00 00 00 02 6f 0f 39 00 00 00 00 00 07 d1 3f fc 3f fc 3f fc 39 00 00 00 00 00 06 f0 55 aa 52 08 07 39 00 00 00 00 00 02 d9 40 39 00 00 00 00 00 02 88 01 39 00 00 00 00 00 02 6f 01 39 00 00 00 00 00 05 88 02 1d 08 63 39 00 00 00 00 00 03 87 1f ff 39 00 00 00 00 00 03 51 07 ff 39 00 00 00 00 00 02 88 01 39 01 00 00 42 00 02 85 01];
			mi,mdss-dsi-local-hbm-hlpm-white-1000nit-command-state = "dsi_hs_mode";
			mi,mdss-dsi-local-hbm-normal-white-110nit-command = <0x39010000 0x6f0 0x55aa5208 0x2390000 0x02 0x6f083900 0x0 0x7d00746 0x6900881 0x39000000 0x10d1 0x1000000 0x67006700 0x0 0xcc00cc39 0x0 0x26f0f 0x39000000 0x7d1 0x3ffc3ffc 0x3ffc3900 0x0 0x6f055aa 0x52080739 0x0 0x2d940 0x39000000 0x288 0x1390000 0x02 0x6f013900 0x0 0x588021d 0x8633900 0x0 0x3871fff 0x39000000 0x351 0x7ff3900 0x0 0x2880139 0x1000042 0x28501>;
			mi,mdss-dsi-local-hbm-normal-white-110nit-command-state = "dsi_hs_mode";
			mi,mdss-dsi-local-hbm-hlpm-white-110nit-command = [39 01 00 00 00 00 06 f0 55 aa 52 08 00 39 00 00 00 00 00 02 38 00 39 00 00 00 00 00 06 f0 55 aa 52 08 02 39 00 00 00 00 00 02 6f 08 39 00 00 00 00 00 07 d0 07 46 06 90 08 81 39 00 00 00 00 00 10 d1 01 00 00 00 67 00 67 00 00 00 00 00 cc 00 cc 39 00 00 00 00 00 02 6f 0f 39 00 00 00 00 00 07 d1 3f fc 3f fc 3f fc 39 00 00 00 00 00 06 f0 55 aa 52 08 07 39 00 00 00 00 00 02 d9 40 39 00 00 00 00 00 02 88 01 39 00 00 00 00 00 02 6f 01 39 00 00 00 00 00 05 88 02 1d 08 63 39 00 00 00 00 00 03 87 1f ff 39 00 00 00 00 00 03 51 07 ff 39 00 00 00 00 00 02 88 01 39 01 00 00 42 00 02 85 01];
			mi,mdss-dsi-local-hbm-hlpm-white-110nit-command-state = "dsi_hs_mode";
			mi,mdss-dsi-local-hbm-normal-green-500nit-command = <0x39010000 0x6f0 0x55aa5208 0x2390000 0x02 0x6f083900 0x0 0x7d00000 0x9190000 0x39000000 0x10d1 0x1000000 0x67006700 0x0 0xcc00cc39 0x0 0x26f0f 0x39000000 0x7d1 0x3ffc3ffc 0x3ffc3900 0x0 0x6f055aa 0x52080739 0x0 0x2d940 0x39000000 0x288 0x1390000 0x02 0x6f013900 0x0 0x588021d 0x8633900 0x0 0x3871fff 0x39000000 0x351 0x7ff3900 0x0 0x2880139 0x1000042 0x28501>;
			mi,mdss-dsi-local-hbm-normal-green-500nit-command-state = "dsi_hs_mode";
			mi,mdss-dsi-local-hbm-off-to-normal-command = [39 01 00 00 00 00 02 53 20 39 00 00 00 00 00 03 51 00 00 39 00 00 00 00 00 03 87 0f ff 39 00 00 00 00 00 02 88 01 39 01 00 00 00 00 02 86 01];
			mi,mdss-dsi-local-hbm-off-to-normal-command-state = "dsi_hs_mode";
			mi,mdss-dsi-local-hbm-off-to-hbm-command = [39 01 00 00 00 00 02 53 20 39 00 00 00 00 00 03 51 00 00 39 00 00 00 00 00 03 87 0f ff 39 00 00 00 00 00 02 88 01 39 01 00 00 00 00 02 86 01];
			mi,mdss-dsi-local-hbm-off-to-hbm-command-state = "dsi_hs_mode";
			mi,mdss-dsi-local-hbm-off-to-hlpm-command = <0x39010000 0x253 0x20390000 0x03 0x51000039 0x0 0x3870f 0xff390000 0x02 0x88013901 0x0 0x2860139 0x0 0x55100 0xf50ffe39 0x1000000 0x23900>;
			mi,mdss-dsi-local-hbm-off-to-hlpm-command-state = "dsi_hs_mode";
			mi,mdss-dsi-local-hbm-off-to-llpm-command = <0x39010000 0x253 0x20390000 0x03 0x51000039 0x0 0x3870f 0xff390000 0x02 0x88013901 0x0 0x2860139 0x0 0x55100 0x1407ff39 0x1000000 0x23900>;
			mi,mdss-dsi-local-hbm-off-to-llpm-command-state = "dsi_hs_mode";
			mi,mdss-dsi-flat-mode-on-command = [39 01 00 00 00 00 06 f0 55 aa 52 08 00 39 00 00 00 00 00 02 5f 00 39 01 00 00 14 00 02 2f 04];
			mi,mdss-dsi-flat-mode-on-command-state = "dsi_hs_mode";
			mi,mdss-dsi-flat-mode-off-command = [39 01 00 00 00 00 06 f0 55 aa 52 08 00 39 00 00 00 00 00 02 5f 01 39 01 00 00 14 00 02 2f 02];
			mi,mdss-dsi-flat-mode-off-command-state = "dsi_hs_mode";
			mi,mdss-dsi-timing-switch-gir-command = [39 01 00 00 14 00 02 2f 04];
			mi,mdss-dsi-timing-switch-gir-command-state = "dsi_hs_mode";
			mi,mdss-dsi-pre-doze-to-off-command = [39 01 00 00 00 00 06 f0 55 aa 52 08 01 39 01 00 00 00 00 02 ce 0c];
			mi,mdss-dsi-pre-doze-to-off-command-state = "dsi_hs_mode";
		};
	};
};
